# AE822FA0E5597BS0_CM55_HP_View register map
Vendor: Alif Semiconductor; Series: E8; File version: 1.0
CPU: CM55 r1p0, selectable endian, MPU, FPU, double-precision FPU, DSP, VTOR, 8 interrupt priority bits, 1 SAU regions
Registers are 32-bit, read-write, reset 0x0 unless marked. A register's access mark holds for its fields unless they carry their own. Offsets are from the block's base; [hi:lo] are bit positions.

## WDT_HP_CTRL
Base 0x40100000
Same registers: WDT_HP_REFRESH 0x40101000
0x00 WDT_WDOGLOAD reset 0xFFFFFFFF — Watchdog Load Register
  [31:0] WDOGLOAD — When this bit field is written, the count is immediately restarted from the new value. The minimum valid value for this field is 0x1.
0x04 WDT_WDOGVALUE ro reset 0xFFFFFFFF — Watchdog Value Register
  [31:0] WDOGVALUE — This bit field gives the current value of the decrementing counter.
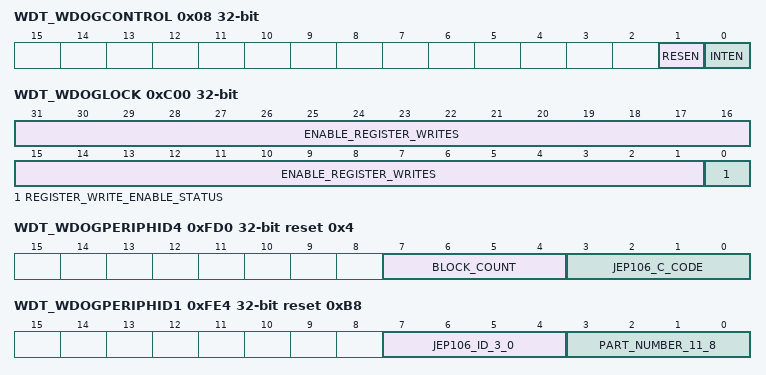
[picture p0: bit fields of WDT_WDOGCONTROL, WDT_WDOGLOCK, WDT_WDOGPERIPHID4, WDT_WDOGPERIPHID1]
0x08 WDT_WDOGCONTROL — Watchdog Control Register
  [1] RESEN — Enables the watchdog reset output, WDOGRES. Acts as a mask for the reset output.
    0=Reset is disabled; 1=Reset is enabled
  [0] INTEN — Enables the interrupt event, WDT_IRQ. Reloads the counter from the value in WDT_WDOGLOAD register when the interrupt is enabled, afterpreviously being disabled.
    0=The counter and the interrupt are disabled; 1=The counter and the interrupt are enabled
0x0C WDT_WDOGINTCLR wo reset not defined — Watchdog Clear Interrupt Register
  [31:0] WDOGINTCLR — A write of any value clears the watchdog interrupt, and reloads the counter from the value in WDT_WDOGLOAD register.
0x10 WDT_WDOGRIS ro — Watchdog Raw Interrupt Status Register
  [0] RAW_WATCHDOG_INTERRUPT — Enables the raw interrupt status from the counter. This value is AND-ed with the value of WDT_WDOGCONTROL[INTEN] bit to create the masked interrupt.
0x14 WDT_WDOGMIS ro — Watchdog Interrupt Status Register
  [0] WATCHDOG_INTERRUPT — Enables the masked interrupt status from the counter. This value is the logical AND of the raw interrupt status with the WDT_WDOGCONTROL[INTEN] bit, and isthe value of the WDT_IRQ.
0xC00 WDT_WDOGLOCK — Watchdog Lock Register
  [31:1] ENABLE_REGISTER_WRITES — Enable write access to all other registers by writing 0x1ACC_E551. Disable write access by writing any other value.
  [0] REGISTER_WRITE_ENABLE_STATUS — Write access status:
    0=Write access to all other registers is enabled; 1=Write access to all other registers is disabled
0xFD0 WDT_WDOGPERIPHID4 ro reset 0x4 — Peripheral ID Register 4
  [7:4] BLOCK_COUNT
  [3:0] JEP106_C_CODE — JEP106 continuation code value
0xFE0 WDT_WDOGPERIPHID0 ro reset 0x24 — Peripheral ID Register 0
  [7:0] PART_NUMBER_7_0 — Part number
0xFE4 WDT_WDOGPERIPHID1 ro reset 0xB8 — Peripheral ID Register 1
  [7:4] JEP106_ID_3_0 — JEP106 identity code [3:0]
  [3:0] PART_NUMBER_11_8 — Part number
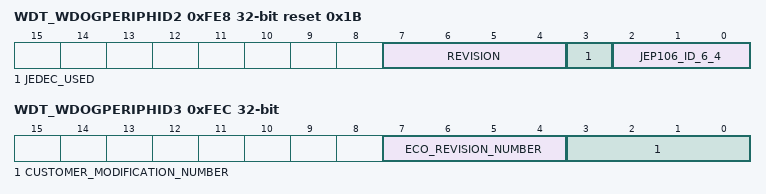
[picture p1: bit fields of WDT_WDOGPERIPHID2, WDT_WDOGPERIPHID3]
0xFE8 WDT_WDOGPERIPHID2 ro reset 0x1B — Peripheral ID Register 2
  [7:4] REVISION — Revision of the TZC-400
  [3] JEDEC_USED — Indicates that the TZC-400 uses a manufacturer identity code allocated by JEDEC according to JEP106.
  [2:0] JEP106_ID_6_4 — JEP106 identity code [6:4]
0xFEC WDT_WDOGPERIPHID3 ro — Peripheral ID Register 3
  [7:4] ECO_REVISION_NUMBER, [3:0] CUSTOMER_MODIFICATION_NUMBER
0xFF0 WDT_WDOGPCELLID0 ro reset 0xD — Component ID Register 0
  [7:0] COMPONENT_ID_0
0xFF4 WDT_WDOGPCELLID1 ro reset 0xF0 — Component ID Register 1
  [7:0] COMPONENT_ID_1
0xFF8 WDT_WDOGPCELLID2 ro reset 0x5 — Component ID Register 2
  [7:0] COMPONENT_ID_2
0xFFC WDT_WDOGPCELLID3 ro reset 0xB1 — Component ID Register 3
  [7:0] COMPONENT_ID_3

## LPRTC0
Base 0x42000000
0x00 LPRTC_CCVR ro — Current Counter Value Register
  [31:0] CURRENT_COUNTER_VALUE — When read, this register contains the current value of the internal counter. This value is always read coherently.
0x04 LPRTC_CMR — Counter Match Register
  [31:0] COUNTER_MATCH — When the internal counter matches this value, an interrupt is generated, provided interrupt generation is enabled. When appropriate, this value is written coherently. Only when all the bytes are written, the value of this register is used by the interrupt detection logic.
0x08 LPRTC_CLR — Counter Load Register
  [31:0] COUNTER_LOAD — Loaded into the counter as counter load value, which is written coherently.
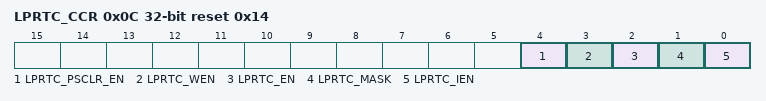
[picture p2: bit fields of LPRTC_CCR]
0x0C LPRTC_CCR reset 0x14 — Counter Control Register
  [4] LPRTC_PSCLR_EN — Controls the usage of the prescaler feature.
    0=Disables the prescaler; 1=Enables the prescaler
  [3] LPRTC_WEN — Controls the wrap enable. Forces the counter to wrap to 0 when a match occurs, instead of waiting until the maximum count is reached.
    0=Disables the wrap; 1=Enables the wrap
  [2] LPRTC_EN — Controls counting in the counter.
    0=Disables the counter; 1=Enables the counter
  [1] LPRTC_MASK — Controls the interrupt mask. Determines whether an internally generated interrupt shall assert the IRQ line.
    0=Unmasks the interrupt; 1=Masks the interrupt
  [0] LPRTC_IEN — Controls the interrupt enable.
    0=Disables the interrupt generation; 1=Enables the interrupt generation
0x10 LPRTC_STAT ro — Interrupt Status Register
  [0] LPRTC_STAT — Masked interrupt status.
    0=Interrupt is inactive. The IRQ line is not asserted.; 1=Interrupt is active. The IRQ line is asserted.
0x14 LPRTC_RSTAT ro — Interrupt Raw Status Register
  [0] LPRTC_RSTAT — Raw interrupt status.
    0=Interrupt is inactive; 1=Interrupt is active
0x18 LPRTC_EOI ro — End-of-Interrupt Register
  [0] LPRTC_EOI — By reading this bit, the match interrupt is cleared. Performing a read-to-clear on interrupt, the interrupt is cleared at the end of the read.
0x1C LPRTC_COMP_VERSION ro reset 0x3230372A — Component Version Register
  [31:0] LPRTC_COMP_VERSION — Component version
0x20 LPRTC_CPSR (reset mask 0xFFFF0000) — Counter Prescaler Register
  [15:0] COUNTER_PRESCALER_VALUE — Counter prescaler value. This bit field is used to prescale the rate at which the LPRTC counter updates. The prescaler value is in the range 1-65536. For example, when this bit field is programmed to 0x8000, and the prescaler is enabled and precise 32.768 kHz clock source is used, the counter increments at a 1 Hz rate. When appropriate, this bit field is written coherently. Only when all the bytes are written, the register is used by the prescaler counter logic. Note: System reset does not affect the value programmed in this bit field. The register will keep its last programmed value until the VDD_BAT power supply is removed.
0x24 LPRTC_CPCVR ro — Current Prescaler Counter Value Register
  [15:0] CURRENT_PRESCALER_COUNTER_VALUE — When read, this bit field provides the current value of the internal prescaler counter. This value is always read coherently.
